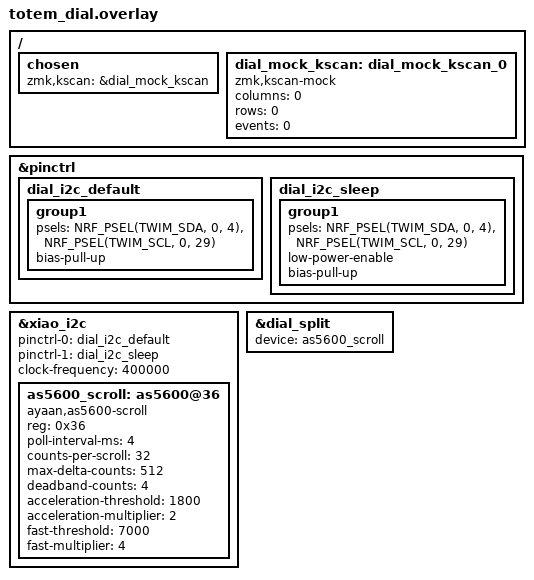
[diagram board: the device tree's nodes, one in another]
/* Standalone XIAO nRF52840 + AS5600 split peripheral. */

#include "totem.dtsi"

/ {
    chosen {
        zmk,kscan = &dial_mock_kscan;
    };

    dial_mock_kscan: dial_mock_kscan_0 {
        compatible = "zmk,kscan-mock";
        columns = <0>;
        rows = <0>;
        events = <0>;
    };
};

/* This XIAO has a failed D5 pin, so route TWIM SCL to D3 instead. */
&pinctrl {
    dial_i2c_default: dial_i2c_default {
        group1 {
            psels = <NRF_PSEL(TWIM_SDA, 0, 4)>,
                    <NRF_PSEL(TWIM_SCL, 0, 29)>;
            bias-pull-up;
        };
    };

    dial_i2c_sleep: dial_i2c_sleep {
        group1 {
            psels = <NRF_PSEL(TWIM_SDA, 0, 4)>,
                    <NRF_PSEL(TWIM_SCL, 0, 29)>;
            low-power-enable;
            bias-pull-up;
        };
    };
};

&xiao_i2c {
    status = "okay";
    pinctrl-0 = <&dial_i2c_default>;
    pinctrl-1 = <&dial_i2c_sleep>;
    pinctrl-names = "default", "sleep";
    clock-frequency = <400000>;

    as5600_scroll: as5600@36 {
        compatible = "ayaan,as5600-scroll";
        reg = <0x36>;
        status = "okay";

        poll-interval-ms = <4>;
        counts-per-scroll = <32>;
        max-delta-counts = <512>;
        deadband-counts = <4>;
        acceleration-threshold = <1800>;
        acceleration-multiplier = <2>;
        fast-threshold = <7000>;
        fast-multiplier = <4>;
    };
};

&dial_split {
    status = "okay";
    device = <&as5600_scroll>;
};
